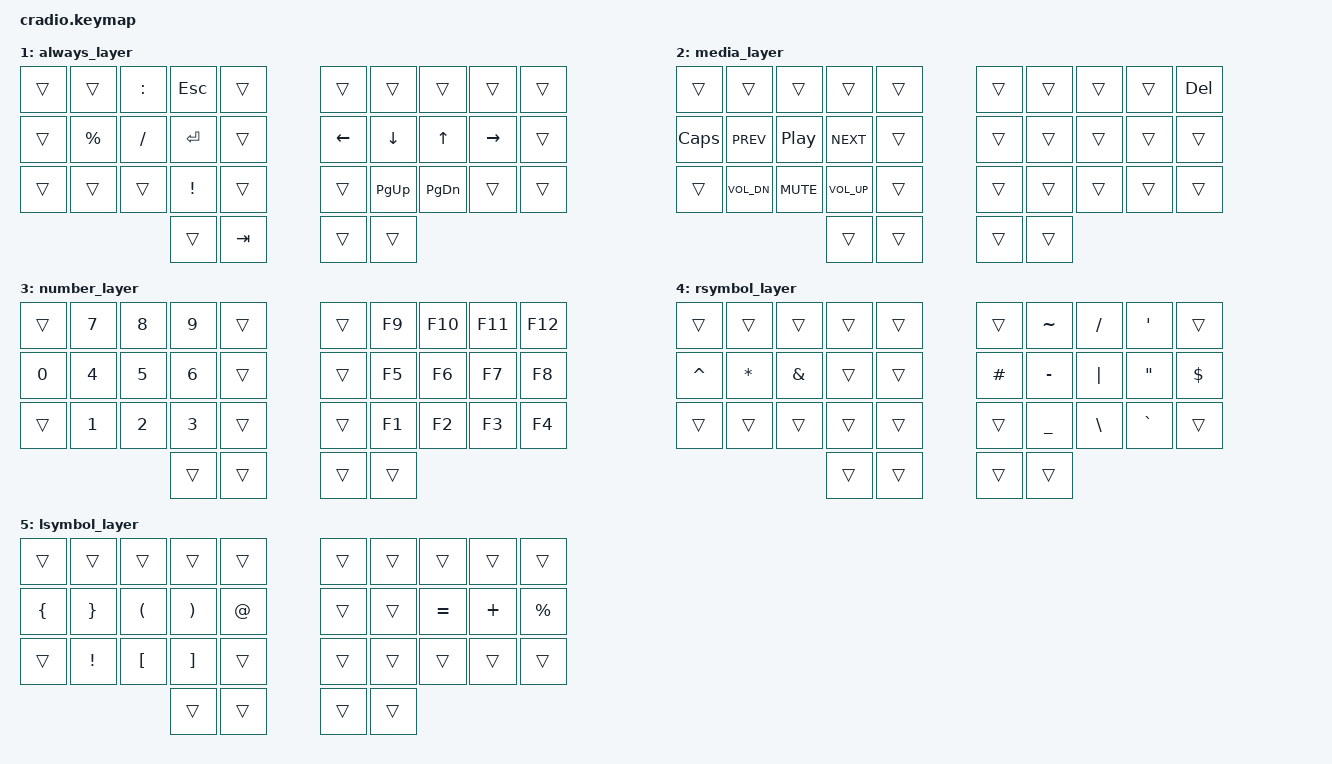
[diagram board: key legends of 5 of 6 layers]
// Copyright (c) 2022 The ZMK Contributors
// SPDX-License-Identifier: MIT

// library includes
#include <behaviors.dtsi>
#include <dt-bindings/zmk/keys.h>
#include <dt-bindings/zmk/bt.h>

// layer definitions
#define DEFAULT  0
#define ALWAYS   1
#define MEDIA    2
#define NUMBERS  3
#define RSYMBOLS 4
#define LSYMBOLS 5

// Home row mods macro
#define HRML(k1,k2,k3,k4) &ht LGUI     k1  &ht LCTRL k2  &ht LSHFT k3  &lt RSYMBOLS k4
#define HRMR(k1,k2,k3,k4) &lt LSYMBOLS k1  &ht RSHFT k2  &ht RCTRL k3  &ht RGUI     k4

/ {
    behaviors {
        ht: hold_tap {
            label = "hold_tap";
            compatible = "zmk,behavior-hold-tap";
            #binding-cells = <2>;
            flavor = "tap-preferred";
            tapping-term-ms = <220>;
            quick-tap-ms = <150>;
            global-quick-tap;
            bindings = <&kp>, <&kp>;
        };
    };

    keymap {
        compatible = "zmk,keymap";
        default_layer {
            bindings = <
        //╭──────────┬──────────┬──────────┬──────────┬──────────╮   ╭──────────┬──────────┬──────────┬──────────┬──────────╮
        //│  Q       │  W       │  E       │  R       │  T       │   │  Y       │  U       │  I       │  O       │  P       │
            &kp Q      &kp W      &kp E      &kp R      &kp T          &kp Y      &kp U      &kp I      &kp O      &kp P
        //├──────────┼──────────┼──────────┼──────────┼──────────┤   ├──────────┼──────────┼──────────┼──────────┼──────────┤
        //│  A       │  S       │  D       │  F       │  G       │   │  H       │  J       │  K       │  L       │ :        │
            HRML(A,        S,         D,         F)     &kp G          &kp H      HRMR(J,        K,         L,       SEMI)
        //├──────────┼──────────┼──────────┼──────────┼──────────┤   ├──────────┼──────────┼──────────┼──────────┼──────────┤
        //│  Z       │  X       │  C       │  V       │  B       │   │  N       │  M       │ , <      │ . >      │ / ?      │
           &ht LALT Z   &kp X      &kp C      &kp V      &kp B          &kp N      &kp M     &kp COMMA  &kp DOT  &ht RALT FSLH
        //╰──────────┴──────────┴──────────┼──────────┼──────────┤   ├──────────┼──────────┼──────────┴──────────┴──────────╯
        //                                 │  Media   │ Backspc  │   │Spc ALWAYS│  Numbers │            
                                            &mo MEDIA   &kp BSPC    &lt ALWAYS SPACE  &mo NUMBERS 
        //                                 ╰──────────┴──────────╯   ╰──────────┴──────────╯
            >;
        };

        always_layer {
            bindings = <
        //╭──────────┬──────────┬──────────┬──────────┬──────────╮   ╭──────────┬──────────┬──────────┬──────────┬──────────╮
        //│          │          │  :       │  esc     │          │   │          │          │          │          │          │
            &trans     &trans    &kp COLON   &kp ESC    &trans         &trans     &trans     &trans     &trans     &trans     
        //├──────────┼──────────┼──────────┼──────────┼──────────┤   ├──────────┼──────────┼──────────┼──────────┼──────────┤
        //│          │  %       │  /       │  enter   │          │   │  Left    │  Down    │  Up      │  Right   │          │
            &trans     &kp PRCNT  &kp FSLH   &kp ENTER  &trans         &kp LEFT   &kp DOWN   &kp UP     &kp RIGHT  &trans    
        //├──────────┼──────────┼──────────┼──────────┼──────────┤   ├──────────┼──────────┼──────────┼──────────┼──────────┤
        //│          │          │          │  !       │          │   │          │ Page Dn  │ Page Up  │          │          │
            &trans     &trans     &trans     &kp EXCL   &trans         &trans     &kp PG_UP  &kp PG_DN  &trans     &trans     
        //╰──────────┴──────────┴──────────┼──────────┼──────────┤   ├──────────┼──────────┼──────────┴──────────┴──────────╯
        //                                 │          │  tab     │   │          │          │
                                             &trans     &kp TAB        &trans     &trans    
        //                                 ╰──────────┴──────────╯   ╰──────────┴──────────╯
            >;
        };

        media_layer {
            bindings = <
        //╭──────────┬──────────┬──────────┬──────────┬──────────╮   ╭──────────┬──────────┬──────────┬──────────┬──────────╮
        //│          │          │          │          │          │   │          │          │          │          │  Delete  │
            &trans     &trans     &trans     &trans     &trans         &trans     &trans     &trans     &trans     &kp DEL
        //├──────────┼──────────┼──────────┼──────────┼──────────┤   ├──────────┼──────────┼──────────┼──────────┼──────────┤
        //│  CAPS    │  Prev    │  Play    │  Next    │          │   │          │          │          │          │          │
            &kp CAPS   &kp C_PREV &kp C_PP  &kp C_NEXT  &trans         &trans     &trans     &trans     &trans     &trans     
        //├──────────┼──────────┼──────────┼──────────┼──────────┤   ├──────────┼──────────┼──────────┼──────────┼──────────┤
        //│          │  Vol Dn  │  Mute    │  Vol Up  │              │          │          │          │          │          │
            &trans   &kp C_VOL_DN &kp C_MUTE &kp C_VOL_UP &trans       &trans     &trans     &trans     &trans     &trans     
        //╰──────────┴──────────┴──────────┼──────────┼──────────┤   ├──────────┼──────────┼──────────┴──────────┴──────────╯
        //                                 │          │          │   │          │          │
                                             &trans     &trans         &trans     &trans      
        //                                 ╰──────────┴──────────╯   ╰──────────┴──────────╯
            >;
        };

        number_layer {
            bindings = <
        //╭──────────┬──────────┬──────────┬──────────┬──────────╮   ╭──────────┬──────────┬──────────┬──────────┬──────────╮
        //│          │  7       │  8       │  9       │          │   │          │ F9       │ F10      │ F11      │ F12      │
            &trans     &kp N7     &kp N8     &kp N9     &trans         &trans     &kp F9     &kp F10    &kp F11    &kp F12
        //├──────────┼──────────┼──────────┼──────────┼──────────┤   ├──────────┼──────────┼──────────┼──────────┼──────────┤
        //│  0       │  4       │  5       │  6       │          │   │          │ F5       │ F6       │ F7       │ F8       │
            &kp N0     &kp N4     &kp N5     &kp N6     &trans         &trans     &kp F5     &kp F6     &kp F7     &kp F8
        //├──────────┼──────────┼──────────┼──────────┼──────────┤   ├──────────┼──────────┼──────────┼──────────┼──────────┤
        //│          │  1       │  2       │  3       │          │   │          │ F1       │ F2       │ F3       │ F4       │
            &trans     &kp N1     &kp N2     &kp N3     &trans         &trans     &kp F1     &kp F2     &kp F3     &kp F4
        //╰──────────┴──────────┴──────────┼──────────┼──────────┤   ├──────────┼──────────┼──────────┴──────────┴──────────╯
                                             &trans     &trans         &trans     &trans
        //                                 ╰──────────┴──────────╯   ╰──────────┴──────────╯
            >;
        };

        rsymbol_layer {
            bindings = <
        //╭──────────┬──────────┬──────────┬──────────┬──────────╮   ╭──────────┬──────────┬──────────┬──────────┬──────────╮
        //│          │          │          │          │          │   │          │  ~       │  /       │  '       │          │
            &trans     &trans     &trans     &trans     &trans         &trans     &kp TILDE  &kp FSLH   &kp SQT    &trans    
        //├──────────┼──────────┼──────────┼──────────┼──────────┤   ├──────────┼──────────┼──────────┼──────────┼──────────┤
        //│  ^       │  *       │  &       │          │          │   │  hash    │  -       │  |       │  "       │  $       │
            &kp CARET  &kp ASTRK  &kp AMPS   &trans     &trans         &kp HASH   &kp MINUS  &kp PIPE   &kp DQT    &kp DLLR
        //├──────────┼──────────┼──────────┼──────────┼──────────┤   ├──────────┼──────────┼──────────┼──────────┼──────────┤
        //│          │          │          │          │          │   │          │  _       │  \       │  `       │          │
            &trans     &trans     &trans     &trans     &trans         &trans    &kp UNDER  &kp BSLH   &kp GRAVE   &trans     
        //╰──────────┴──────────┴──────────┼──────────┼──────────┤   ├──────────┼──────────┼──────────┴──────────┴──────────╯
        //                                 │          │          │   │          │          │
                                             &trans     &trans         &trans     &trans      
        //                                 ╰──────────┴──────────╯   ╰──────────┴──────────╯
            >;
        };

        lsymbol_layer {
            bindings = <
        //╭──────────┬──────────┬──────────┬──────────┬──────────╮   ╭──────────┬──────────┬──────────┬──────────┬──────────╮
        //│          │          │          │          │          │   │          │          │          │          │          │
            &trans     &trans     &trans     &trans     &trans         &trans     &trans     &trans     &trans     &trans     
        //├──────────┼──────────┼──────────┼──────────┼──────────┤   ├──────────┼──────────┼──────────┼──────────┼──────────┤
        //│  {       │  }       │  (       │  )       │  @       │   │          │          │  =       │  +       │  %       │
            &kp LBRC   &kp RBRC   &kp LPAR   &kp RPAR   &kp AT         &trans     &trans     &kp EQUAL  &kp PLUS   &kp PRCNT
        //├──────────┼──────────┼──────────┼──────────┼──────────┤   ├──────────┼──────────┼──────────┼──────────┼──────────┤
        //│          │  !       │  [       │  ]       │          │   │          │          │          │          │          │
            &trans     &kp EXCL   &kp LBKT   &kp RBKT   &trans         &trans     &trans     &trans     &trans     &trans       
        //╰──────────┴──────────┴──────────┼──────────┼──────────┤   ├──────────┼──────────┼──────────┴──────────┴──────────╯
        //                                 │          │          │   │          │          │
                                             &trans     &trans         &trans     &trans      
        //                                 ╰──────────┴──────────╯   ╰──────────┴──────────╯
            >;
        };
    };
};
